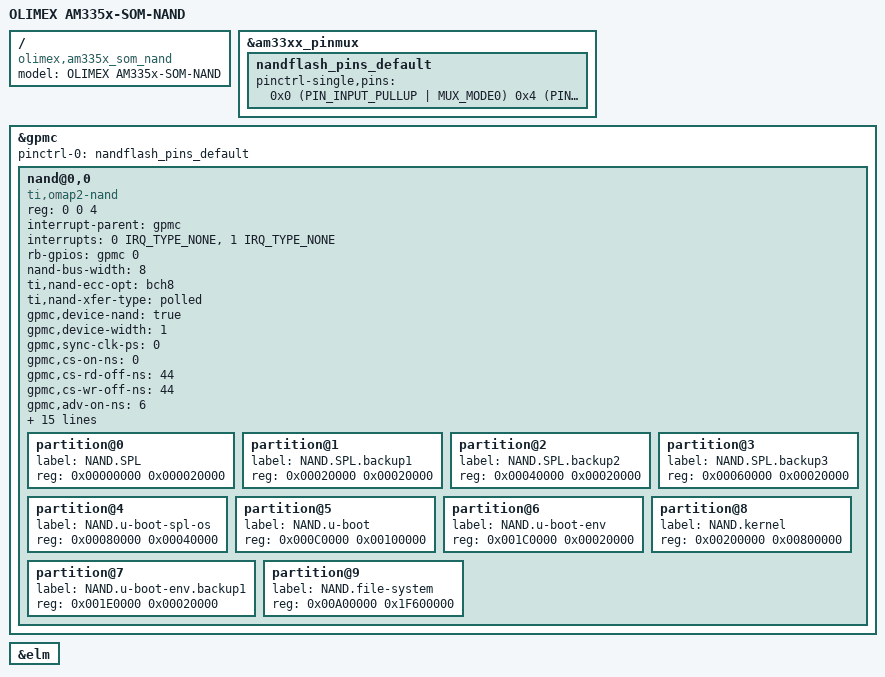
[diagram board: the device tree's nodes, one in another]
/*
 * Copyright (C) 2012 Texas Instruments Incorporated - http://www.ti.com/
 *
 * This program is free software; you can redistribute it and/or modify
 * it under the terms of the GNU General Public License version 2 as
 * published by the Free Software Foundation.
 */
/dts-v1/;

#include "am335x-olimex.dtsi"
#include <dt-bindings/interrupt-controller/irq.h>

/ {
    model = "OLIMEX AM335x-SOM-NAND";
    compatible = "olimex,am335x_som_nand", "ti,am33xx";
};

&am33xx_pinmux {

  nandflash_pins_default: nandflash_pins_default {
    pinctrl-single,pins = <
			0x0 (PIN_INPUT_PULLUP | MUX_MODE0)	/* gpmc_ad0.gpmc_ad0 */
			0x4 (PIN_INPUT_PULLUP | MUX_MODE0)	/* gpmc_ad1.gpmc_ad1 */
			0x8 (PIN_INPUT_PULLUP | MUX_MODE0)	/* gpmc_ad2.gpmc_ad2 */
			0xc (PIN_INPUT_PULLUP | MUX_MODE0)	/* gpmc_ad3.gpmc_ad3 */
			0x10 (PIN_INPUT_PULLUP | MUX_MODE0)	/* gpmc_ad4.gpmc_ad4 */
			0x14 (PIN_INPUT_PULLUP | MUX_MODE0)	/* gpmc_ad5.gpmc_ad5 */
			0x18 (PIN_INPUT_PULLUP | MUX_MODE0)	/* gpmc_ad6.gpmc_ad6 */
			0x1c (PIN_INPUT_PULLUP | MUX_MODE0)	/* gpmc_ad7.gpmc_ad7 */
			0x70 (PIN_INPUT | MUX_MODE0)		/* gpmc_wait0.gpmc_wait0 */
			0x7c (PIN_OUTPUT | MUX_MODE0)		/* gpmc_csn0.gpmc_csn0  */
			0x90 (PIN_OUTPUT | MUX_MODE0)		/* gpmc_advn_ale.gpmc_advn_ale */
			0x94 (PIN_OUTPUT | MUX_MODE0)		/* gpmc_oen_ren.gpmc_oen_ren */
			0x98 (PIN_OUTPUT | MUX_MODE0)		/* gpmc_wen.gpmc_wen */
			0x9c (PIN_OUTPUT | MUX_MODE0)		/* gpmc_be0n_cle.gpmc_be0n_cle */
    >;
	};
};

&gpmc {
	pinctrl-names = "default";
	pinctrl-0 = <&nandflash_pins_default>;
	ranges = <0 0 0x08000000 0x20000000>;
	status = "okay";

	nand@0,0 {
		compatible = "ti,omap2-nand";
		reg = <0 0 4>;
		interrupt-parent = <&gpmc>;
		interrupts = <0 IRQ_TYPE_NONE>, <1 IRQ_TYPE_NONE>;
		rb-gpios = <&gpmc 0 GPIO_ACTIVE_HIGH>;
		nand-bus-width = <8>;
		ti,nand-ecc-opt = "bch8";
		ti,nand-xfer-type = "polled";

		gpmc,device-nand = "true";
		gpmc,device-width = <1>;
		gpmc,sync-clk-ps = <0>;
		gpmc,cs-on-ns = <0>;
		gpmc,cs-rd-off-ns = <44>;
		gpmc,cs-wr-off-ns = <44>;
		gpmc,adv-on-ns = <6>;
		gpmc,adv-rd-off-ns = <34>;
		gpmc,adv-wr-off-ns = <44>;
		gpmc,we-on-ns = <0>;
		gpmc,we-off-ns = <40>;
		gpmc,oe-on-ns = <0>;
		gpmc,oe-off-ns = <54>;
		gpmc,access-ns = <64>;
		gpmc,rd-cycle-ns = <82>;
		gpmc,wr-cycle-ns = <82>;
		gpmc,bus-turnaround-ns = <0>;
		gpmc,cycle2cycle-delay-ns = <0>;
		gpmc,clk-activation-ns = <0>;
		gpmc,wr-access-ns = <40>;
		gpmc,wr-data-mux-bus-ns = <0>;

		#address-cells = <1>;
		#size-cells = <1>;
		ti,elm-id = <&elm>;

		partition@0 {
			label = "NAND.SPL";
			reg = <0x00000000 0x000020000>;
		};
		partition@1 {
			label = "NAND.SPL.backup1";
			reg = <0x00020000 0x00020000>;
		};
		partition@2 {
			label = "NAND.SPL.backup2";
			reg = <0x00040000 0x00020000>;
		};
		partition@3 {
			label = "NAND.SPL.backup3";
			reg = <0x00060000 0x00020000>;
		};
		partition@4 {
			label = "NAND.u-boot-spl-os";
			reg = <0x00080000 0x00040000>;
		};
		partition@5 {
			label = "NAND.u-boot";
			reg = <0x000C0000 0x00100000>;
		};
		partition@6 {
			label = "NAND.u-boot-env";
			reg = <0x001C0000 0x00020000>;
		};
		partition@7 {
			label = "NAND.u-boot-env.backup1";
			reg = <0x001E0000 0x00020000>;
		};
		partition@8 {
			label = "NAND.kernel";
			reg = <0x00200000 0x00800000>;
		};
		partition@9 {
			label = "NAND.file-system";
			reg = <0x00A00000 0x1F600000>;
		};
	};
};

&elm {
	status = "okay";
};
